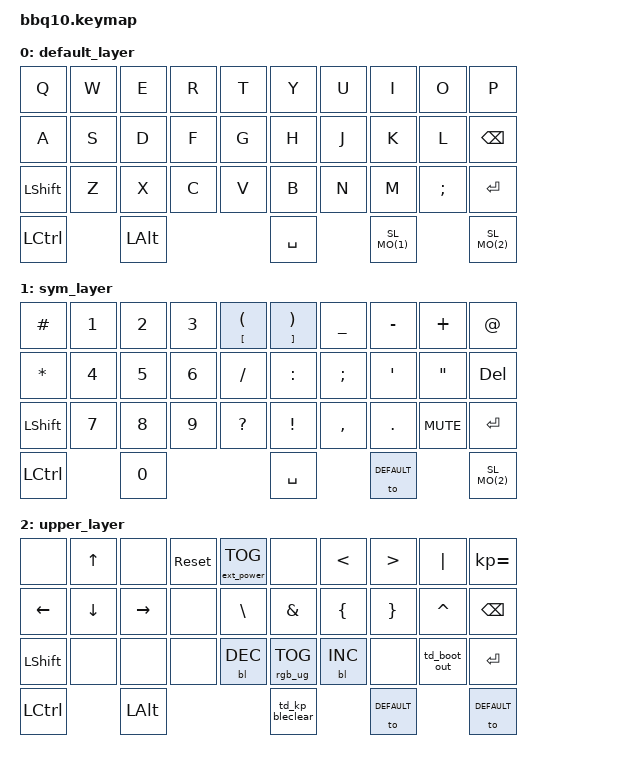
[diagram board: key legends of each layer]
/*
 * Copyright (c) 2025 daliben123
 *
 * SPDX-License-Identifier: MIT
 */

#include <behaviors.dtsi>
#include <dt-bindings/zmk/keys.h>
#include <dt-bindings/zmk/bt.h>
#include <dt-bindings/zmk/outputs.h>
#include <dt-bindings/zmk/mouse.h>
#include <dt-bindings/zmk/backlight.h>
#include <dt-bindings/zmk/ext_power.h>
#include <dt-bindings/zmk/rgb.h>


#define DEFAULT 0
#define SYM 1
#define UPPER 2

#define SL_MO(layer) &sl_mo layer layer //tap -> sticky layer, hold -> momentary layer


&sl {
    release-after-ms = <3000>;
    };

/ {
    behaviors {
        td0: tap_dance_0 {
            compatible = "zmk,behavior-tap-dance";
            #binding-cells = <0>;
            tapping-term-ms = <400>;
            bindings = <&mkp LCLK>, <&bt BT_CLR>;
        };
    };

    behaviors {
        td_boot_out: td_boot_out {
            compatible = "zmk,behavior-tap-dance";
            #binding-cells = <0>;
            tapping-term-ms = <400>;            // 单/双击最大间隔，可调整
            bindings = <&bootloader>, <&out OUT_TOG>;
            // Tap → &bootloader
            // Double tap → &out OUT_TOG
        };
    };

    behaviors {
        td_kp_bleclear: td_kp_bleclear {
            compatible = "zmk,behavior-tap-dance";
            #binding-cells = <0>;
            tapping-term-ms = <400>;            // 单/双击最大间隔，可调整
            bindings = <&kp SPACE>, <&bt BT_CLR>;
            // Tap → &kp space
            // Double tap → &bt BT_CLEAR
        };
    };

    behaviors {
        hm: homerow_mods {
            compatible = "zmk,behavior-hold-tap";
            #binding-cells = <2>;
            tapping-term-ms = <400>;
            bindings = <&kp &kp>;
        };
    };
    
    behaviors {
    sl_mo: behavior_sl_mo {
        compatible = "zmk,behavior-hold-tap";
        #binding-cells = <2>;
        flavor = "hold-preferred";      /* 单击优先 */
        tapping-term-ms = <450>;       /* 长按阈值 */
        bindings = <&mo &sl>;          /* hold=MO, tap=SL */
        };
    };


    keymap {
        compatible = "zmk,keymap";

        default_layer {

            bindings = <
//         --------------------------------------------------------------------------------------------------------------------------         
// |     Q      |     W    |     E    |     R    |      T      |       Y        |       U        |        I        |       O      |      P        |     
// |     A      |     S    |     D    |     F    |      G      |       H        |       J        |        K        |       L      |      ←        |  
// |     alt    |     Z    |     X    |     C    |      V      |       B        |       N        |        M        |       $      |    Enter      |   
//        |         aA     |         0           |           SPACE              |         SYM         |        aA          |       
//        -----------------------------------------------------------------------------------------------------------------

    &kp Q        &kp W      &kp E       &kp R     &kp T         &kp Y             &kp U            &kp I            &kp O            &kp P
    &kp A        &kp S      &kp D       &kp F     &kp G         &kp H             &kp J            &kp K            &kp L            &kp BSPC
    &kp LSHFT    &kp Z      &kp X       &kp C     &kp V         &kp B             &kp N            &kp M            &kp SEMI         &kp ENTER
    &kp LCTRL               &kp LALT                            &kp SPACE                          SL_MO(1)                          SL_MO(2)
            >;
        };


        sym_layer {

            bindings = <        
    &kp HASH     &kp N1     &kp N2      &kp N3    &mt LBKT LPAR &mt RBKT RPAR     &kp UNDER        &kp MINUS        &kp PLUS         &kp AT
    &kp STAR     &kp N4     &kp N5      &kp N6    &kp SLASH     &kp COLON         &kp SEMI         &kp APOS         &kp DQT          &kp DEL
    &kp LSHFT    &kp N7     &kp N8      &kp N9    &kp QMARK     &kp EXCL          &kp COMMA        &kp DOT          &kp C_MUTE       &kp ENTER
    &kp LCTRL               &kp N0                              &kp SPACE                          &to DEFAULT                       SL_MO(2)
            >;
        };

        upper_layer {

            bindings = <
    &none        &kp UP     &none       &sys_reset &ext_power EP_TOG &none            &kp LT           &kp GT          &kp PIPE         &kp KP_EQUAL
    &kp LEFT     &kp DOWN   &kp RIGHT   &none      &kp BSLH          &kp AMPS         &kp LBRC         &kp RBRC        &kp CARET        &kp BSPC
    &kp LSHFT    &none      &none       &none      &bl BL_DEC        &rgb_ug RGB_TOG  &bl BL_INC       &none           &td_boot_out     &kp ENTER
    &kp LCTRL               &kp LALT                                 &td_kp_bleclear                   &to DEFAULT                      &to DEFAULT
            >;
        };
    };
};
